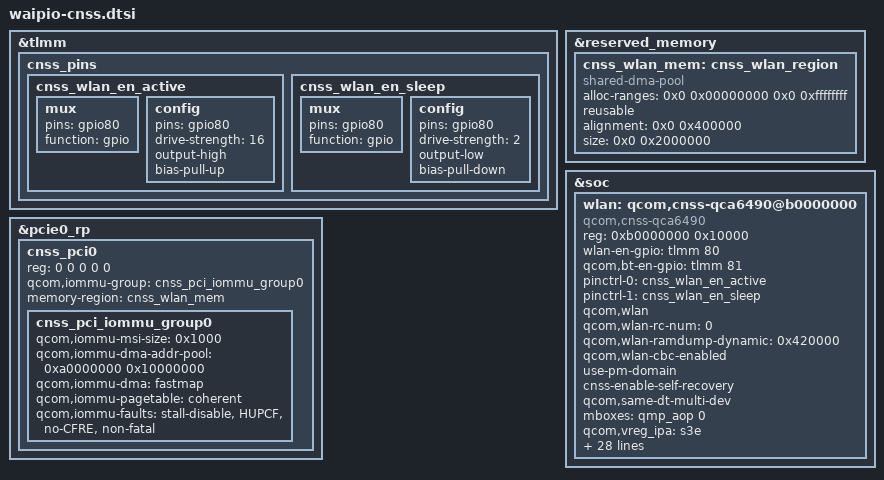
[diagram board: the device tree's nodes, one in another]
#include <dt-bindings/interconnect/qcom,waipio.h>

&tlmm {
	cnss_pins {
		cnss_wlan_en_active: cnss_wlan_en_active {
			mux {
				pins = "gpio80";
				function = "gpio";
			};

			config {
				pins = "gpio80";
				drive-strength = <16>;
				output-high;
				bias-pull-up;
			};
		};

		cnss_wlan_en_sleep: cnss_wlan_en_sleep {
			mux {
				pins = "gpio80";
				function = "gpio";
			};

			config {
				pins = "gpio80";
				drive-strength = <2>;
				output-low;
				bias-pull-down;
			};
		};
	};
};

&reserved_memory {
	cnss_wlan_mem: cnss_wlan_region {
		compatible = "shared-dma-pool";
		alloc-ranges = <0x0 0x00000000 0x0 0xffffffff>;
		reusable;
		alignment = <0x0 0x400000>;
		size = <0x0 0x2000000>;
	};
};

&soc {
	wlan: qcom,cnss-qca6490@b0000000 {
		compatible = "qcom,cnss-qca6490";
		reg = <0xb0000000 0x10000>;
		reg-names = "smmu_iova_ipa";
		wlan-en-gpio = <&tlmm 80 0>;
		qcom,bt-en-gpio = <&tlmm 81 0>;
		pinctrl-names = "wlan_en_active", "wlan_en_sleep";
		pinctrl-0 = <&cnss_wlan_en_active>;
		pinctrl-1 = <&cnss_wlan_en_sleep>;
		qcom,wlan;
		qcom,wlan-rc-num = <0>;
		qcom,wlan-ramdump-dynamic = <0x420000>;
		qcom,wlan-cbc-enabled;
		use-pm-domain;
		cnss-enable-self-recovery;
		qcom,same-dt-multi-dev;
		mboxes = <&qmp_aop 0>;
		qcom,vreg_ipa="s3e";
		qcom,xo-clk-gpio = <&tlmm 204 0>;

		vdd-wlan-aon-supply = <&S2E>;
		qcom,vdd-wlan-aon-config = <1012000 1012000 0 0 1>;
		vdd-wlan-dig-supply = <&S11B>;
		qcom,vdd-wlan-dig-config = <966000 966000 0 0 1>;
		vdd-wlan-io-supply = <&S10B>;
		qcom,vdd-wlan-io-config = <1800000 1800000 0 0 1>;
		vdd-wlan-rfa1-supply = <&S1C>;
		qcom,vdd-wlan-rfa1-config = <1900000 2100000 0 0 1>;
		vdd-wlan-rfa2-supply = <&S12B>;
		qcom,vdd-wlan-rfa2-config = <1350000 1350000 0 0 1>;
		wlan-ant-switch-supply = <&L7E>;
		qcom,wlan-ant-switch-config = <2800000 2800000 0 0 1>;

		interconnects =
		<&pcie_noc MASTER_PCIE_0 &pcie_noc SLAVE_ANOC_PCIE_GEM_NOC>,
		<&gem_noc MASTER_ANOC_PCIE_GEM_NOC &mc_virt SLAVE_EBI1>;
		interconnect-names = "pcie_to_memnoc", "memnoc_to_ddr";

		qcom,icc-path-count = <2>;
		qcom,bus-bw-cfg-count = <7>;
		qcom,bus-bw-cfg =
		/** ICC Path 1 **/
		<0 0>, /* no vote */
		/* idle: 0-18 Mbps snoc/anoc: 100 Mhz ddr: 451.2 MHz */
		<2250 1600000>,
		/* low: 18-60 Mbps snoc/anoc: 100 Mhz ddr: 451.2 MHz */
		<7500 1600000>,
		/* medium: 60-240 Mbps snoc/anoc: 100 Mhz ddr: 451.2 MHz */
		<30000 1600000>,
		/* high: 240-1200 Mbps snoc/anoc: 100 Mhz ddr: 451.2 MHz */
		<100000 1600000>,
		/* very high: > 1200 Mbps snoc/anoc: 403 Mhz ddr: 451.2 MHz */
		<175000 6448000>,
		/* low (latency critical): 18-60 Mbps snoc/anoc: 200 Mhz
		 * ddr: 547.2 MHz
		 */
		<7500 3200000>,

		/** ICC Path 2 **/
		<0 0>,
		<2250 1804800>,
		<7500 1804800>,
		<30000 1804800>,
		<100000 1804800>,
		<175000 6220800>,
		<7500 2188800>;
	};
};

&pcie0_rp {
	#address-cells = <5>;
	#size-cells = <0>;

	cnss_pci0: cnss_pci0 {
		reg = <0 0 0 0 0>;
		qcom,iommu-group = <&cnss_pci_iommu_group0>;
		memory-region = <&cnss_wlan_mem>;

		#address-cells = <1>;
		#size-cells = <1>;

		cnss_pci_iommu_group0: cnss_pci_iommu_group0 {
			qcom,iommu-msi-size = <0x1000>;
			qcom,iommu-dma-addr-pool = <0xa0000000 0x10000000>;
			qcom,iommu-dma = "fastmap";
			qcom,iommu-pagetable = "coherent";
			qcom,iommu-faults = "stall-disable", "HUPCF", "no-CFRE",
					    "non-fatal";
		};
	};
};
